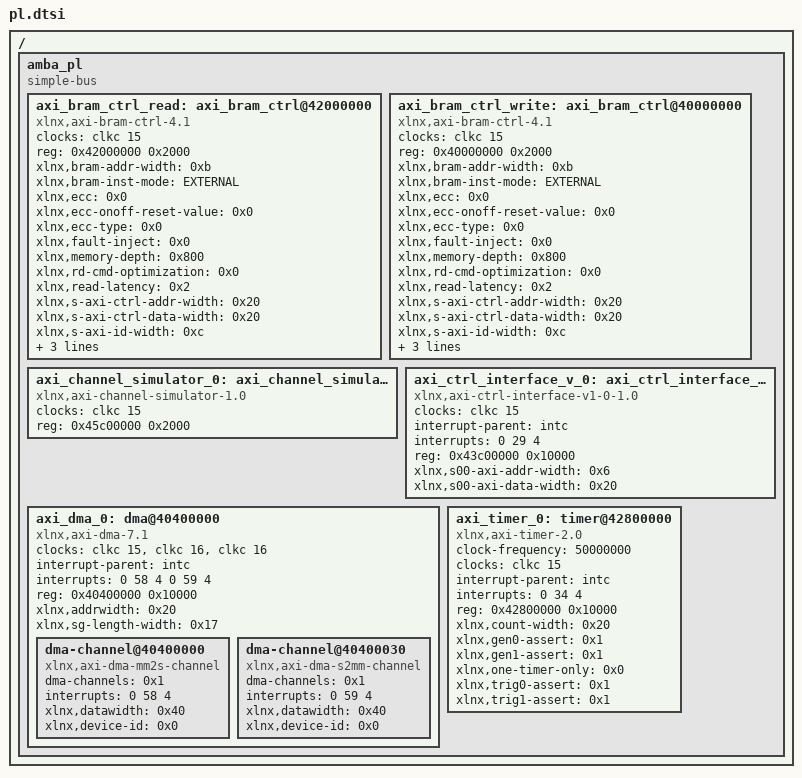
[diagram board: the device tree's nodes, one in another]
/*
 * CAUTION: This file is automatically generated by Xilinx.
 * Version: HSI 
 * Today is: Sat May 21 17:27:45 2022
 */


/ {
	amba_pl: amba_pl {
		#address-cells = <1>;
		#size-cells = <1>;
		compatible = "simple-bus";
		ranges ;
		axi_bram_ctrl_read: axi_bram_ctrl@42000000 {
			clock-names = "s_axi_aclk";
			clocks = <&clkc 15>;
			compatible = "xlnx,axi-bram-ctrl-4.1";
			reg = <0x42000000 0x2000>;
			xlnx,bram-addr-width = <0xb>;
			xlnx,bram-inst-mode = "EXTERNAL";
			xlnx,ecc = <0x0>;
			xlnx,ecc-onoff-reset-value = <0x0>;
			xlnx,ecc-type = <0x0>;
			xlnx,fault-inject = <0x0>;
			xlnx,memory-depth = <0x800>;
			xlnx,rd-cmd-optimization = <0x0>;
			xlnx,read-latency = <0x2>;
			xlnx,s-axi-ctrl-addr-width = <0x20>;
			xlnx,s-axi-ctrl-data-width = <0x20>;
			xlnx,s-axi-id-width = <0xc>;
			xlnx,s-axi-supports-narrow-burst = <0x0>;
			xlnx,select-xpm = <0x1>;
			xlnx,single-port-bram = <0x1>;
		};
		axi_bram_ctrl_write: axi_bram_ctrl@40000000 {
			clock-names = "s_axi_aclk";
			clocks = <&clkc 15>;
			compatible = "xlnx,axi-bram-ctrl-4.1";
			reg = <0x40000000 0x2000>;
			xlnx,bram-addr-width = <0xb>;
			xlnx,bram-inst-mode = "EXTERNAL";
			xlnx,ecc = <0x0>;
			xlnx,ecc-onoff-reset-value = <0x0>;
			xlnx,ecc-type = <0x0>;
			xlnx,fault-inject = <0x0>;
			xlnx,memory-depth = <0x800>;
			xlnx,rd-cmd-optimization = <0x0>;
			xlnx,read-latency = <0x2>;
			xlnx,s-axi-ctrl-addr-width = <0x20>;
			xlnx,s-axi-ctrl-data-width = <0x20>;
			xlnx,s-axi-id-width = <0xc>;
			xlnx,s-axi-supports-narrow-burst = <0x0>;
			xlnx,select-xpm = <0x1>;
			xlnx,single-port-bram = <0x1>;
		};
		axi_channel_simulator_0: axi_channel_simulator@45c00000 {
			clock-names = "S_AXI_ACLK";
			clocks = <&clkc 15>;
			compatible = "xlnx,axi-channel-simulator-1.0";
			reg = <0x45c00000 0x2000>;
		};
		axi_ctrl_interface_v_0: axi_ctrl_interface_v1_0@43c00000 {
			clock-names = "s00_axi_aclk";
			clocks = <&clkc 15>;
			compatible = "xlnx,axi-ctrl-interface-v1-0-1.0";
			interrupt-names = "bram_read_irq";
			interrupt-parent = <&intc>;
			interrupts = <0 29 4>;
			reg = <0x43c00000 0x10000>;
			xlnx,s00-axi-addr-width = <0x6>;
			xlnx,s00-axi-data-width = <0x20>;
		};
		axi_dma_0: dma@40400000 {
			#dma-cells = <1>;
			clock-names = "s_axi_lite_aclk", "m_axi_mm2s_aclk", "m_axi_s2mm_aclk";
			clocks = <&clkc 15>, <&clkc 16>, <&clkc 16>;
			compatible = "xlnx,axi-dma-7.1", "xlnx,axi-dma-1.00.a";
			interrupt-names = "mm2s_introut", "s2mm_introut";
			interrupt-parent = <&intc>;
			interrupts = <0 58 4 0 59 4>;
			reg = <0x40400000 0x10000>;
			xlnx,addrwidth = <0x20>;
			xlnx,sg-length-width = <0x17>;
			dma-channel@40400000 {
				compatible = "xlnx,axi-dma-mm2s-channel";
				dma-channels = <0x1>;
				interrupts = <0 58 4>;
				xlnx,datawidth = <0x40>;
				xlnx,device-id = <0x0>;
			};
			dma-channel@40400030 {
				compatible = "xlnx,axi-dma-s2mm-channel";
				dma-channels = <0x1>;
				interrupts = <0 59 4>;
				xlnx,datawidth = <0x40>;
				xlnx,device-id = <0x0>;
			};
		};
		axi_timer_0: timer@42800000 {
			clock-frequency = <50000000>;
			clock-names = "s_axi_aclk";
			clocks = <&clkc 15>;
			compatible = "xlnx,axi-timer-2.0", "xlnx,xps-timer-1.00.a";
			interrupt-names = "interrupt";
			interrupt-parent = <&intc>;
			interrupts = <0 34 4>;
			reg = <0x42800000 0x10000>;
			xlnx,count-width = <0x20>;
			xlnx,gen0-assert = <0x1>;
			xlnx,gen1-assert = <0x1>;
			xlnx,one-timer-only = <0x0>;
			xlnx,trig0-assert = <0x1>;
			xlnx,trig1-assert = <0x1>;
		};
	};
};
